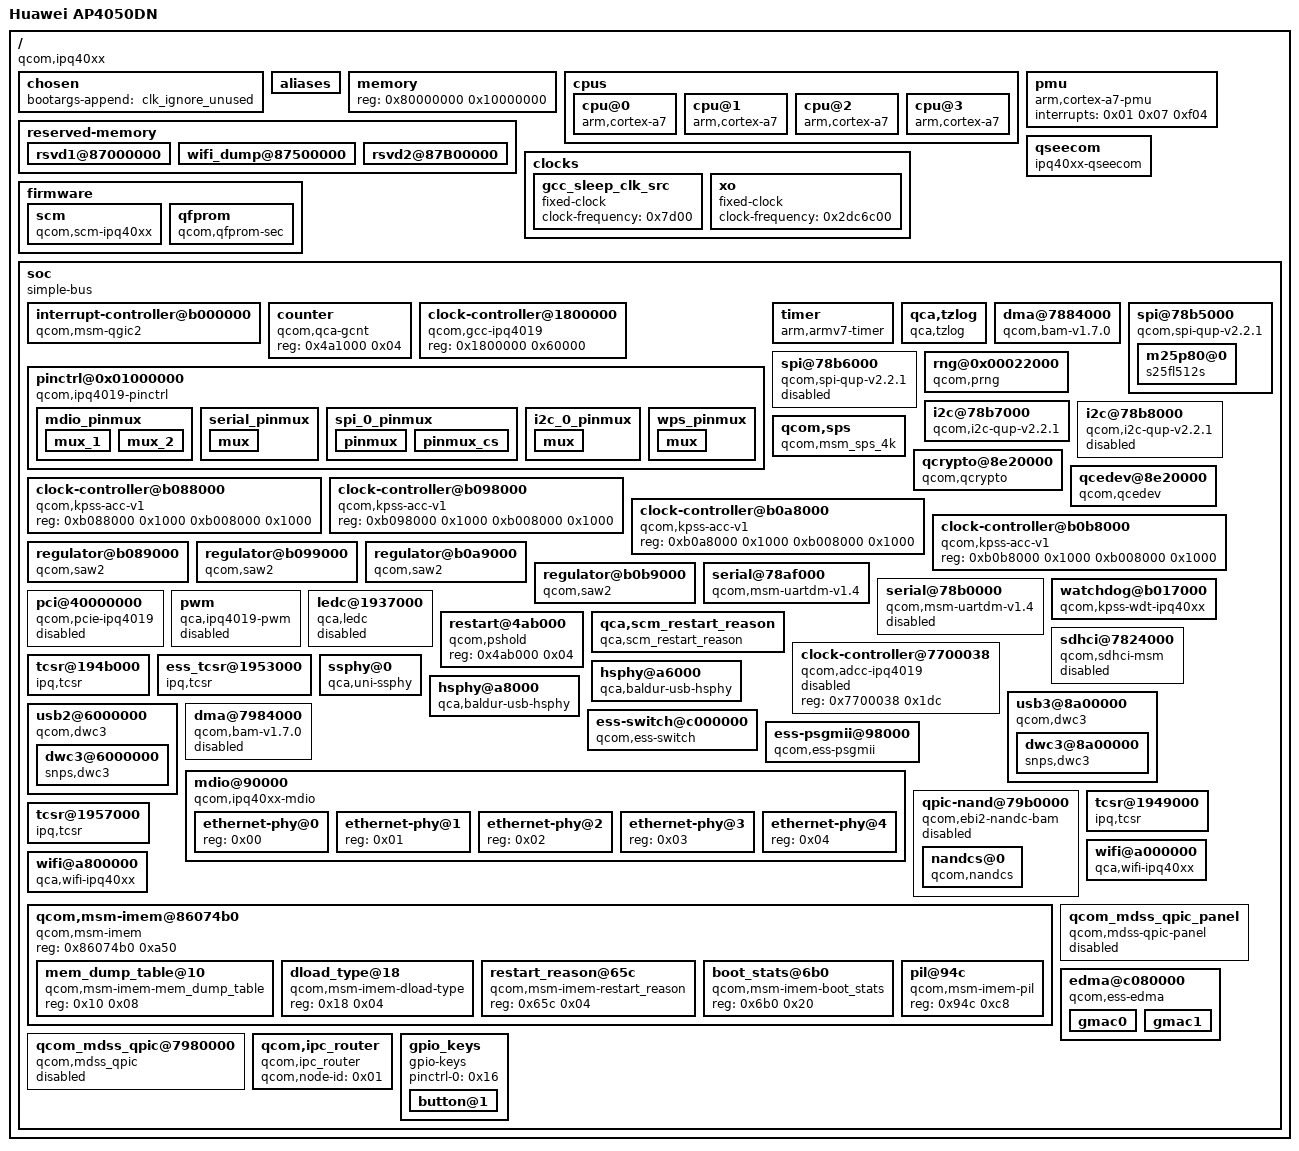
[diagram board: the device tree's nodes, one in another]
/dts-v1/;

/ {
	#address-cells = <0x01>;
	#size-cells = <0x01>;
	model = "Huawei AP4050DN";
	compatible = "qcom,ipq40xx";
	interrupt-parent = <0x01>;

	chosen {
		bootargs-append = " clk_ignore_unused";
	};

	aliases {
		spi0 = "/soc/spi@78b5000";
		spi1 = "/soc/spi@78b6000";
		i2c0 = "/soc/i2c@78b7000";
		i2c1 = "/soc/i2c@78b8000";
		ethernet0 = "/soc/edma/gmac0";
		ethernet1 = "/soc/edma/gmac1";
	};

	memory {
		device_type = "memory";
		reg = <0x80000000 0x10000000>;
	};

	cpus {
		#address-cells = <0x01>;
		#size-cells = <0x00>;

		cpu@0 {
			device_type = "cpu";
			compatible = "arm,cortex-a7";
			enable-method = "qcom,kpss-acc-v1";
			qcom,acc = <0x02>;
			qcom,saw = <0x03>;
			reg = <0x00>;
			clocks = <0x04 0x09>;
			clock-frequency = <0x00>;
			operating-points = <0xbb80 0x10c8e0 0x30d40 0x10c8e0 0x7a120 0x10c8e0 0xa4100 0x10c8e0 0xaece0 0x10c8e0>;
			clock-latency = <0x186a0>;
		};

		cpu@1 {
			device_type = "cpu";
			compatible = "arm,cortex-a7";
			enable-method = "qcom,kpss-acc-v1";
			qcom,acc = <0x05>;
			qcom,saw = <0x06>;
			reg = <0x01>;
			clocks = <0x04 0x09>;
			clock-frequency = <0x00>;
		};

		cpu@2 {
			device_type = "cpu";
			compatible = "arm,cortex-a7";
			enable-method = "qcom,kpss-acc-v1";
			qcom,acc = <0x07>;
			qcom,saw = <0x08>;
			reg = <0x02>;
			clocks = <0x04 0x09>;
			clock-frequency = <0x00>;
		};

		cpu@3 {
			device_type = "cpu";
			compatible = "arm,cortex-a7";
			enable-method = "qcom,kpss-acc-v1";
			qcom,acc = <0x09>;
			qcom,saw = <0x0a>;
			reg = <0x03>;
			clocks = <0x04 0x09>;
			clock-frequency = <0x00>;
		};
	};

	pmu {
		compatible = "arm,cortex-a7-pmu";
		interrupts = <0x01 0x07 0xf04>;
	};

	reserved-memory {
		#address-cells = <0x01>;
		#size-cells = <0x01>;
		ranges;

		rsvd1@87000000 {
			reg = <0x87000000 0x100000>;
			no-map;
		};

		wifi_dump@87500000 {
			reg = <0x87500000 0x100000>;
			no-map;
		};

		rsvd2@87B00000 {
			reg = <0x87b00000 0x500000>;
			no-map;
		};
	};

	clocks {

		gcc_sleep_clk_src {
			compatible = "fixed-clock";
			clock-frequency = <0x7d00>;
			#clock-cells = <0x00>;
			linux,phandle = <0x10>;
			phandle = <0x10>;
		};

		xo {
			compatible = "fixed-clock";
			clock-frequency = <0x2dc6c00>;
			#clock-cells = <0x00>;
		};
	};

	qseecom {
		compatible = "ipq40xx-qseecom";
		mem-start = <0x87b80000>;
		mem-size = <0x280000>;
	};

	firmware {

		scm {
			compatible = "qcom,scm-ipq40xx";
		};

		qfprom {
			compatible = "qcom,qfprom-sec";
			img-addr = <0x87500000>;
			img-size = <0x600000>;
		};
	};

	soc {
		#address-cells = <0x01>;
		#size-cells = <0x01>;
		ranges;
		compatible = "simple-bus";

		interrupt-controller@b000000 {
			compatible = "qcom,msm-qgic2";
			interrupt-controller;
			#interrupt-cells = <0x03>;
			reg = <0xb000000 0x1000 0xb002000 0x1000>;
			linux,phandle = <0x01>;
			phandle = <0x01>;
		};

		counter {
			compatible = "qcom,qca-gcnt";
			reg = <0x4a1000 0x04>;
		};

		clock-controller@1800000 {
			compatible = "qcom,gcc-ipq4019";
			#clock-cells = <0x01>;
			#reset-cells = <0x01>;
			reg = <0x1800000 0x60000>;
			linux,phandle = <0x04>;
			phandle = <0x04>;
		};

		pinctrl@0x01000000 {
			compatible = "qcom,ipq4019-pinctrl";
			reg = <0x1000000 0x300000>;
			gpio-controller;
			#gpio-cells = <0x02>;
			interrupt-controller;
			#interrupt-cells = <0x02>;
			interrupts = <0x00 0xd0 0x00>;
			linux,phandle = <0x0d>;
			phandle = <0x0d>;

			mdio_pinmux {
				linux,phandle = <0x14>;
				phandle = <0x14>;

				mux_1 {
					pins = "gpio53";
					function = "mdio1";
					bias-pull-up;
				};

				mux_2 {
					pins = "gpio52";
					function = "mdc";
					bias-pull-up;
				};
			};

			serial_pinmux {
				linux,phandle = <0x0f>;
				phandle = <0x0f>;

				mux {
					pins = "gpio60\0gpio61";
					function = "blsp_uart0";
					bias-disable;
				};
			};

			spi_0_pinmux {
				linux,phandle = <0x0c>;
				phandle = <0x0c>;

				pinmux {
					function = "blsp_spi0";
					pins = "gpio55\0gpio56\0gpio57";
					bias-disable;
				};

				pinmux_cs {
					function = "gpio";
					pins = "gpio54";
					bias-disable;
					output-high;
				};
			};

			i2c_0_pinmux {
				linux,phandle = <0x0e>;
				phandle = <0x0e>;

				mux {
					pins = "gpio58\0gpio59";
					function = "blsp_i2c0";
					bias-disable;
				};
			};

			wps_pinmux {
				linux,phandle = <0x16>;
				phandle = <0x16>;

				mux {
					pins = "gpio63";
					bias-pull-up;
				};
			};
		};

		timer {
			compatible = "arm,armv7-timer";
			interrupts = <0x01 0x02 0xf08 0x01 0x03 0xf08 0x01 0x04 0xf08 0x01 0x01 0xf08>;
			clock-frequency = <0x2dc6c00>;
			always-on;
		};

		qca,tzlog {
			compatible = "qca,tzlog";
		};

		dma@7884000 {
			compatible = "qcom,bam-v1.7.0";
			reg = <0x7884000 0x23000>;
			interrupts = <0x00 0xee 0x00>;
			clocks = <0x04 0x15>;
			clock-names = "bam_clk";
			#dma-cells = <0x01>;
			qcom,ee = <0x00>;
			status = "ok";
			linux,phandle = <0x0b>;
			phandle = <0x0b>;
		};

		spi@78b5000 {
			compatible = "qcom,spi-qup-v2.2.1";
			reg = <0x78b5000 0x600>;
			interrupts = <0x00 0x5f 0x04>;
			clocks = <0x04 0x17 0x04 0x15>;
			clock-names = "core\0iface";
			#address-cells = <0x01>;
			#size-cells = <0x00>;
			dmas = <0x0b 0x05 0x0b 0x04>;
			dma-names = "rx\0tx";
			status = "ok";
			pinctrl-0 = <0x0c>;
			pinctrl-names = "default";
			cs-gpios = <0x0d 0x36 0x00>;
			num-cs = <0x01>;

			m25p80@0 {
				#address-cells = <0x01>;
				#size-cells = <0x01>;
				compatible = "s25fl512s";
				reg = <0x00>;
				linux,modalias = "m25p80\0s25fl512s";
				spi-max-frequency = <0x16e3600>;
				use-default-sizes;
			};
		};

		spi@78b6000 {
			compatible = "qcom,spi-qup-v2.2.1";
			reg = <0x78b6000 0x600>;
			interrupts = <0x00 0x60 0x04>;
			clocks = <0x04 0x19 0x04 0x15>;
			clock-names = "core\0iface";
			#address-cells = <0x01>;
			#size-cells = <0x00>;
			dmas = <0x0b 0x07 0x0b 0x06>;
			dma-names = "rx\0tx";
			status = "disabled";
		};

		rng@0x00022000 {
			compatible = "qcom,prng";
			reg = <0x22000 0x140>;
			clocks = <0x04 0x2b>;
			clock-names = "core";
		};

		i2c@78b7000 {
			compatible = "qcom,i2c-qup-v2.2.1";
			#address-cells = <0x01>;
			#size-cells = <0x00>;
			reg = <0x78b7000 0x600>;
			interrupts = <0x00 0x61 0x04>;
			clocks = <0x04 0x15 0x04 0x16>;
			clock-names = "iface\0core";
			clock-frequency = <0x186a0>;
			qup-clock-frequency = <0x122ae10>;
			dmas = <0x0b 0x09 0x0b 0x08>;
			dma-names = "rx\0tx";
			status = "ok";
			pinctrl-0 = <0x0e>;
			pinctrl-names = "default";
		};

		i2c@78b8000 {
			compatible = "qcom,i2c-qup-v2.2.1";
			#address-cells = <0x01>;
			#size-cells = <0x00>;
			reg = <0x78b8000 0x600>;
			interrupts = <0x00 0x62 0x04>;
			clocks = <0x04 0x15 0x04 0x18>;
			clock-names = "iface\0core";
			clock-frequency = <0x186a0>;
			qup-clock-frequency = <0x122ae10>;
			dmas = <0x0b 0x0b 0x0b 0x0a>;
			dma-names = "rx\0tx";
			status = "disabled";
		};

		qcom,sps {
			compatible = "qcom,msm_sps_4k";
			qcom,device-type = <0x03>;
			qcom,pipe-attr-ee;
		};

		qcrypto@8e20000 {
			compatible = "qcom,qcrypto";
			reg = <0x8e20000 0x20000 0x8e04000 0x20000>;
			reg-names = "crypto-base\0crypto-bam-base";
			interrupts = <0x00 0xcf 0x00>;
			qcom,bam-pipe-pair = <0x01>;
			qcom,ce-hw-instance = <0x00>;
			qcom,ce-hw-shared = <0x01>;
			qcom,ce-device = <0x00>;
			qcom,ce-opp-freq = <0x7735940>;
			clocks = <0x04 0x23 0x04 0x22 0x04 0x21>;
			clock-names = "core_clk\0bus_clk\0iface_clk";
			status = "ok";
		};

		qcedev@8e20000 {
			compatible = "qcom,qcedev";
			reg = <0x8e20000 0x20000 0x8e04000 0x20000>;
			reg-names = "crypto-base\0crypto-bam-base";
			interrupts = <0x00 0xcf 0x00>;
			qcom,bam-pipe-pair = <0x01>;
			qcom,ce-hw-instance = <0x00>;
			qcom,ce-hw-shared = <0x01>;
			qcom,ce-device = <0x00>;
			qcom,ce-opp-freq = <0x7735940>;
			clocks = <0x04 0x23 0x04 0x22 0x04 0x21>;
			clock-names = "core_clk\0bus_clk\0iface_clk";
			status = "ok";
		};

		clock-controller@b088000 {
			compatible = "qcom,kpss-acc-v1";
			reg = <0xb088000 0x1000 0xb008000 0x1000>;
			linux,phandle = <0x02>;
			phandle = <0x02>;
		};

		clock-controller@b098000 {
			compatible = "qcom,kpss-acc-v1";
			reg = <0xb098000 0x1000 0xb008000 0x1000>;
			linux,phandle = <0x05>;
			phandle = <0x05>;
		};

		clock-controller@b0a8000 {
			compatible = "qcom,kpss-acc-v1";
			reg = <0xb0a8000 0x1000 0xb008000 0x1000>;
			linux,phandle = <0x07>;
			phandle = <0x07>;
		};

		clock-controller@b0b8000 {
			compatible = "qcom,kpss-acc-v1";
			reg = <0xb0b8000 0x1000 0xb008000 0x1000>;
			linux,phandle = <0x09>;
			phandle = <0x09>;
		};

		regulator@b089000 {
			compatible = "qcom,saw2";
			reg = <0x2089000 0x1000 0xb009000 0x1000>;
			regulator;
			linux,phandle = <0x03>;
			phandle = <0x03>;
		};

		regulator@b099000 {
			compatible = "qcom,saw2";
			reg = <0xb099000 0x1000 0xb009000 0x1000>;
			regulator;
			linux,phandle = <0x06>;
			phandle = <0x06>;
		};

		regulator@b0a9000 {
			compatible = "qcom,saw2";
			reg = <0xb0a9000 0x1000 0xb009000 0x1000>;
			regulator;
			linux,phandle = <0x08>;
			phandle = <0x08>;
		};

		regulator@b0b9000 {
			compatible = "qcom,saw2";
			reg = <0xb0b9000 0x1000 0xb009000 0x1000>;
			regulator;
			linux,phandle = <0x0a>;
			phandle = <0x0a>;
		};

		serial@78af000 {
			compatible = "qcom,msm-uartdm-v1.4\0qcom,msm-uartdm";
			reg = <0x78af000 0x200>;
			interrupts = <0x00 0x6b 0x00>;
			status = "ok";
			clocks = <0x04 0x1a 0x04 0x15>;
			clock-names = "core\0iface";
			tx-watermark = <0x00>;
			pinctrl-0 = <0x0f>;
			pinctrl-names = "default";
		};

		serial@78b0000 {
			compatible = "qcom,msm-uartdm-v1.4\0qcom,msm-uartdm";
			reg = <0x78b0000 0x200>;
			interrupts = <0x00 0x6c 0x00>;
			status = "disabled";
			clocks = <0x04 0x1b 0x04 0x15>;
			clock-names = "core\0iface";
			dmas = <0x0b 0x03 0x0b 0x02>;
			dma-names = "rx\0tx";
		};

		watchdog@b017000 {
			compatible = "qcom,kpss-wdt-ipq40xx";
			reg = <0xb017000 0x40 0x87b70000 0x10000>;
			reg-names = "kpss_wdt\0tlv";
			interrupt-names = "bark_irq";
			interrupts = <0x00 0x03 0x00>;
			clocks = <0x10>;
			timeout-sec = <0x0a>;
			wdt-max-timeout = <0x20>;
			status = "ok";
		};

		pci@40000000 {
			compatible = "qcom,pcie-ipq4019";
			reg = <0x40000000 0xf1d 0x40000f20 0xa8 0x80000 0x2000 0x40100000 0x1000>;
			reg-names = "dbi\0elbi\0parf\0config";
			device_type = "pci";
			linux,pci-domain = <0x00>;
			bus-range = <0x00 0xff>;
			num-lanes = <0x01>;
			#address-cells = <0x03>;
			#size-cells = <0x02>;
			ranges = <0x81000000 0x00 0x40200000 0x40200000 0x00 0x100000 0x82000000 0x00 0x40400000 0x40400000 0x00 0x10000000>;
			interrupts = <0x00 0x8d 0x00>;
			interrupt-names = "msi";
			#interrupt-cells = <0x01>;
			interrupt-map-mask = <0x00 0x00 0x00 0x07>;
			interrupt-map = <0x00 0x00 0x00 0x01 0x01 0x00 0x8e 0x04 0x00 0x00 0x00 0x02 0x01 0x00 0x8f 0x04 0x00 0x00 0x00 0x03 0x01 0x00 0x90 0x04 0x00 0x00 0x00 0x04 0x01 0x00 0x91 0x04>;
			clocks = <0x04 0x27 0x04 0x28 0x04 0x29>;
			clock-names = "ahb\0axi_m\0axi_s";
			resets = <0x04 0x1c 0x04 0x1b 0x04 0x1a 0x04 0x19 0x04 0x18 0x04 0x17 0x04 0x16 0x04 0x15 0x04 0x14 0x04 0x13 0x04 0x12 0x04 0x11>;
			reset-names = "axi_m\0axi_s\0pipe\0axi_m_vmid\0axi_s_xpu\0parf\0phy\0axi_m_sticky\0pipe_sticky\0pwr\0ahb\0phy_ahb";
			status = "disabled";
		};

		pwm {
			compatible = "qca,ipq4019-pwm";
			clocks = <0x04 0x14>;
			clock-names = "core";
			pwm-base-index = <0x00>;
			used-pwm-indices = <0x01 0x01 0x01 0x01>;
			status = "disabled";
		};

		ledc@1937000 {
			compatible = "qca,ledc";
			reg = <0x1937000 0x20070>;
			reg-names = "ledc_base_addr";
			qcom,tcsr_ledc_values = <0x320193 0x14720800 0x20d 0x00 0x00 0xffffffff 0x00 0x07 0x7d0010 0x00 0x10482090 0x3fffdfc>;
			qcom,ledc_blink_indices_cnt = <0x00>;
			qcom,ledc_blink_indices = <0x00>;
			status = "disabled";
		};

		restart@4ab000 {
			compatible = "qcom,pshold";
			reg = <0x4ab000 0x04>;
		};

		qca,scm_restart_reason {
			compatible = "qca,scm_restart_reason";
		};

		sdhci@7824000 {
			compatible = "qcom,sdhci-msm";
			reg = <0x7824900 0x11c 0x7824000 0x800>;
			reg-names = "hc_mem\0core_mem";
			interrupts = <0x00 0x7b 0x00 0x00 0x8a 0x00>;
			interrupt-names = "hc_irq\0pwr_irq";
			qcom,bus-width = <0x08>;
			qcom,max_clk = <0xb71b000>;
			clocks = <0x04 0x2f 0x04 0x2e>;
			clock-names = "core_clk\0iface_clk";
			qcom,large-address-bus;
			qcom,disable-aggressive-pm;
			status = "disabled";
		};

		clock-controller@7700038 {
			compatible = "qcom,adcc-ipq4019";
			#clock-cells = <0x01>;
			#reset-cells = <0x01>;
			reg = <0x7700038 0x1dc>;
			status = "disabled";
		};

		tcsr@194b000 {
			compatible = "ipq,tcsr";
			reg = <0x194b000 0x100>;
			ipq,usb-hsphy-mode-select = <0xe700e7>;
			status = "ok";
		};

		ess_tcsr@1953000 {
			compatible = "ipq,tcsr";
			reg = <0x1953000 0x1000>;
			ipq,ess-interface-select = <0x00>;
		};

		ssphy@0 {
			compatible = "qca,uni-ssphy";
			reg = <0x9a000 0x800>;
			reg-names = "phy_base";
			resets = <0x04 0x0c>;
			reset-names = "por_rst";
			qca,host = <0x01>;
			#phy-cells = <0x00>;
			status = "ok";
			linux,phandle = <0x12>;
			phandle = <0x12>;
		};

		hsphy@a6000 {
			compatible = "qca,baldur-usb-hsphy";
			reg = <0xa6000 0x40 0x8af8800 0x100>;
			reg-names = "phy_base\0qscratch_base";
			resets = <0x04 0x0d 0x04 0x0e>;
			reset-names = "por_rst\0srif_rst";
			qca,host = <0x01>;
			#phy-cells = <0x00>;
			status = "ok";
			linux,phandle = <0x11>;
			phandle = <0x11>;
		};

		hsphy@a8000 {
			compatible = "qca,baldur-usb-hsphy";
			reg = <0xa8000 0x40>;
			reg-names = "phy_base";
			resets = <0x04 0x0f 0x04 0x10>;
			reset-names = "por_rst\0srif_rst";
			qca,host = <0x01>;
			#phy-cells = <0x00>;
			status = "ok";
			linux,phandle = <0x13>;
			phandle = <0x13>;
		};

		usb3@8a00000 {
			compatible = "qcom,dwc3";
			#address-cells = <0x01>;
			#size-cells = <0x01>;
			ranges;
			reg = <0x8af8800 0x100>;
			reg-names = "qscratch_base";
			clocks = <0x04 0x38 0x04 0x39 0x04 0x3a>;
			clock-names = "master\0sleep\0mock_utmi";
			qca,host = <0x01>;
			status = "ok";

			dwc3@8a00000 {
				compatible = "snps,dwc3";
				reg = <0x8a00000 0xf8000>;
				interrupts = <0x00 0x84 0x00>;
				#phy-cells = <0x00>;
				phys = <0x11 0x12>;
				phy-names = "usb2-phy\0usb3-phy";
				tx-fifo-resize;
				dr_mode = "host";
				usb2-susphy-quirk;
				usb2-host-discon-quirk;
				usb2-host-discon-phy-misc-reg = <0x24>;
				usb2-host-discon-mask = <0x100>;
			};
		};

		usb2@6000000 {
			compatible = "qcom,dwc3";
			#address-cells = <0x01>;
			#size-cells = <0x01>;
			ranges;
			reg = <0x60f8800 0x100>;
			reg-names = "qscratch_base";
			clocks = <0x04 0x35 0x04 0x36 0x04 0x37>;
			clock-names = "master\0sleep\0mock_utmi";
			qca,host = <0x01>;
			status = "ok";

			dwc3@6000000 {
				compatible = "snps,dwc3";
				reg = <0x6000000 0xf8000>;
				interrupts = <0x00 0x88 0x00>;
				#phy-cells = <0x00>;
				phys = <0x13>;
				phy-names = "usb2-phy";
				tx-fifo-resize;
				dr_mode = "host";
				usb2-susphy-quirk;
				usb2-host-discon-quirk;
				usb2-host-discon-phy-misc-reg = <0x24>;
				usb2-host-discon-mask = <0x100>;
			};
		};

		dma@7984000 {
			compatible = "qcom,bam-v1.7.0";
			reg = <0x7984000 0x1a000>;
			interrupts = <0x00 0x65 0x00>;
			clocks = <0x04 0x2d>;
			clock-names = "bam_clk";
			#dma-cells = <0x01>;
			qcom,ee = <0x00>;
			status = "disabled";
			linux,phandle = <0x15>;
			phandle = <0x15>;
		};

		ess-switch@c000000 {
			compatible = "qcom,ess-switch";
			reg = <0xc000000 0x80000>;
			switch_access_mode = "local bus";
			resets = <0x04 0x1d 0x04 0x4e 0x04 0x4f 0x04 0x50 0x04 0x51 0x04 0x52>;
			reset-names = "ess_rst\0ess_mac1_clk_dis\0ess_mac2_clk_dis\0ess_mac3_clk_dis\0ess_mac4_clk_dis\0ess_mac5_clk_dis";
			clocks = <0x04 0x24>;
			clock-names = "ess_clk";
			switch_cpu_bmp = <0x01>;
			switch_lan_bmp = <0x1e>;
			switch_wan_bmp = <0x20>;
			switch_mac_mode = <0x00>;
			switch_initvlas = <0x7c 0x54>;
		};

		ess-psgmii@98000 {
			compatible = "qcom,ess-psgmii";
			reg = <0x98000 0x800>;
			psgmii_access_mode = "local bus";
			resets = <0x04 0x4d>;
			reset-names = "psgmii_rst";
		};

		mdio@90000 {
			#address-cells = <0x01>;
			#size-cells = <0x01>;
			compatible = "qcom,ipq40xx-mdio";
			reg = <0x90000 0x64>;
			status = "ok";
			pinctrl-0 = <0x14>;
			pinctrl-names = "default";
			bias-disable;
			phy-reset-gpio = <0x0d 0x3b 0x00>;

			ethernet-phy@0 {
				reg = <0x00>;
			};

			ethernet-phy@1 {
				reg = <0x01>;
			};

			ethernet-phy@2 {
				reg = <0x02>;
			};

			ethernet-phy@3 {
				reg = <0x03>;
			};

			ethernet-phy@4 {
				reg = <0x04>;
			};
		};

		qpic-nand@79b0000 {
			compatible = "qcom,ebi2-nandc-bam\0qcom,msm-nand";
			reg = <0x79b0000 0x1000>;
			#address-cells = <0x01>;
			#size-cells = <0x00>;
			clocks = <0x04 0x2d 0x04 0x2c>;
			clock-names = "core\0aon";
			dmas = <0x15 0x00 0x15 0x01 0x15 0x02>;
			dma-names = "tx\0rx\0cmd";
			status = "disabled";

			nandcs@0 {
				compatible = "qcom,nandcs";
				reg = <0x00>;
				#address-cells = <0x01>;
				#size-cells = <0x01>;
				nand-ecc-strength = <0x04>;
				nand-ecc-step-size = <0x200>;
				nand-bus-width = <0x08>;
			};
		};

		tcsr@1949000 {
			compatible = "ipq,tcsr";
			reg = <0x1949000 0x100>;
			ipq,wifi_glb_cfg = <0x41000000>;
		};

		tcsr@1957000 {
			compatible = "ipq,tcsr";
			reg = <0x1957000 0x100>;
			ipq,wifi_noc_memtype_m0_m2 = <0x2222222>;
		};

		wifi@a000000 {
			compatible = "qca,wifi-ipq40xx";
			reg = <0xa000000 0x200000>;
			core-id = <0x00>;
			resets = <0x04 0x00 0x04 0x01 0x04 0x02 0x04 0x03 0x04 0x04 0x04 0x05>;
			reset-names = "wifi_cpu_init\0wifi_radio_srif\0wifi_radio_warm\0wifi_radio_cold\0wifi_core_warm\0wifi_core_cold";
			clocks = <0x04 0x3b 0x04 0x3c 0x04 0x3d>;
			clock-names = "wifi_wcss_cmd\0wifi_wcss_ref\0wifi_wcss_rtc";
			interrupts = <0x00 0x20 0x01 0x00 0x21 0x01 0x00 0x22 0x01 0x00 0x23 0x01 0x00 0x24 0x01 0x00 0x25 0x01 0x00 0x26 0x01 0x00 0x27 0x01 0x00 0x28 0x01 0x00 0x29 0x01 0x00 0x2a 0x01 0x00 0x2b 0x01 0x00 0x2c 0x01 0x00 0x2d 0x01 0x00 0x2e 0x01 0x00 0x2f 0x01 0x00 0xa8 0x00>;
			interrupt-names = "msi0\0msi1\0msi2\0msi3\0msi4\0msi5\0msi6\0msi7\0msi8\0msi9\0msi10\0msi11\0msi12\0msi13\0msi14\0msi15\0legacy";
			status = "ok";
			qca,msi_addr = <0xb006040>;
			qca,msi_base = <0x40>;
			wifi-led-gpios = <0x0d 0x3a 0x01>;
		};

		wifi@a800000 {
			compatible = "qca,wifi-ipq40xx";
			reg = <0xa800000 0x200000>;
			core-id = <0x01>;
			resets = <0x04 0x06 0x04 0x07 0x04 0x08 0x04 0x09 0x04 0x0a 0x04 0x0b>;
			reset-names = "wifi_cpu_init\0wifi_radio_srif\0wifi_radio_warm\0wifi_radio_cold\0wifi_core_warm\0wifi_core_cold";
			clocks = <0x04 0x3e 0x04 0x3f 0x04 0x40>;
			clock-names = "wifi_wcss_cmd\0wifi_wcss_ref\0wifi_wcss_rtc";
			interrupts = <0x00 0x30 0x01 0x00 0x31 0x01 0x00 0x32 0x01 0x00 0x33 0x01 0x00 0x34 0x01 0x00 0x35 0x01 0x00 0x36 0x01 0x00 0x37 0x01 0x00 0x38 0x01 0x00 0x39 0x01 0x00 0x3a 0x01 0x00 0x3b 0x01 0x00 0x3c 0x01 0x00 0x3d 0x01 0x00 0x3e 0x01 0x00 0x3f 0x01 0x00 0xa9 0x00>;
			interrupt-names = "msi0\0msi1\0msi2\0msi3\0msi4\0msi5\0msi6\0msi7\0msi8\0msi9\0msi10\0msi11\0msi12\0msi13\0msi14\0msi15\0legacy";
			status = "ok";
			qca,msi_addr = <0xb006040>;
			qca,msi_base = <0x50>;
			wifi-led-gpios = <0x0d 0x3a 0x01>;
		};

		qcom,msm-imem@86074b0 {
			compatible = "qcom,msm-imem";
			reg = <0x86074b0 0xa50>;
			ranges = <0x00 0x86074b0 0xa50>;
			#address-cells = <0x01>;
			#size-cells = <0x01>;

			mem_dump_table@10 {
				compatible = "qcom,msm-imem-mem_dump_table";
				reg = <0x10 0x08>;
			};

			dload_type@18 {
				compatible = "qcom,msm-imem-dload-type";
				reg = <0x18 0x04>;
			};

			restart_reason@65c {
				compatible = "qcom,msm-imem-restart_reason";
				reg = <0x65c 0x04>;
			};

			boot_stats@6b0 {
				compatible = "qcom,msm-imem-boot_stats";
				reg = <0x6b0 0x20>;
			};

			pil@94c {
				compatible = "qcom,msm-imem-pil";
				reg = <0x94c 0xc8>;
			};
		};

		qcom_mdss_qpic@7980000 {
			compatible = "qcom,mdss_qpic";
			reg = <0x7980000 0x24000>;
			interrupts = <0x00 0x6a 0x00>;
			clocks = <0x04 0x2d 0x04 0x2c>;
			clock-names = "core\0aon";
			dmas = <0x15 0x06>;
			dma-names = "chan";
			status = "disabled";
		};

		qcom_mdss_qpic_panel {
			compatible = "qcom,mdss-qpic-panel";
			label = "qpic lcd panel";
			qcom,mdss-pan-res = <0x320 0x1e0>;
			qcom,mdss-pan-bpp = <0x12>;
			qcom,refresh_rate = <0x3c>;
			status = "disabled";
		};

		edma@c080000 {
			compatible = "qcom,ess-edma";
			reg = <0xc080000 0x8000>;
			qcom,page-mode = <0x00>;
			qcom,rx-head-buf-size = <0x604>;
			qcom,num-gmac = <0x02>;
			qcom,mdio-supported;
			interrupts = <0x00 0x41 0x01 0x00 0x42 0x01 0x00 0x43 0x01 0x00 0x44 0x01 0x00 0x45 0x01 0x00 0x46 0x01 0x00 0x47 0x01 0x00 0x48 0x01 0x00 0x49 0x01 0x00 0x4a 0x01 0x00 0x4b 0x01 0x00 0x4c 0x01 0x00 0x4d 0x01 0x00 0x4e 0x01 0x00 0x4f 0x01 0x00 0x50 0x01 0x00 0xf0 0x01 0x00 0xf1 0x01 0x00 0xf2 0x01 0x00 0xf3 0x01 0x00 0xf4 0x01 0x00 0xf5 0x01 0x00 0xf6 0x01 0x00 0xf7 0x01 0x00 0xf8 0x01 0x00 0xf9 0x01 0x00 0xfa 0x01 0x00 0xfb 0x01 0x00 0xfc 0x01 0x00 0xfd 0x01 0x00 0xfe 0x01 0x00 0xff 0x01>;

			gmac0 {
				local-mac-address = [00 00 00 00 00 00];
				qcom,phy-mdio-addr = <0x04>;
				qcom,poll-required = <0x01>;
				qcom,poll-required-dynamic = <0x01>;
				qcom,forced-speed = <0x3e8>;
				qcom,forced-duplex = <0x01>;
				vlan-tag = <0x02 0x20>;
			};

			gmac1 {
				local-mac-address = [00 00 00 00 00 00];
				qcom,poll-required-dynamic = <0x01>;
				vlan-tag = <0x01 0x1e>;
			};
		};

		qcom,ipc_router {
			compatible = "qcom,ipc_router";
			qcom,node-id = <0x01>;
		};

		gpio_keys {
			pinctrl-0 = <0x16>;
			pinctrl-names = "default";
			compatible = "gpio-keys";

			button@1 {
				label = "wps";
				linux,code = <0x211>;
				gpios = <0x0d 0x3f 0x01>;
				linux,input-type = <0x01>;
			};
		};
	};
};
